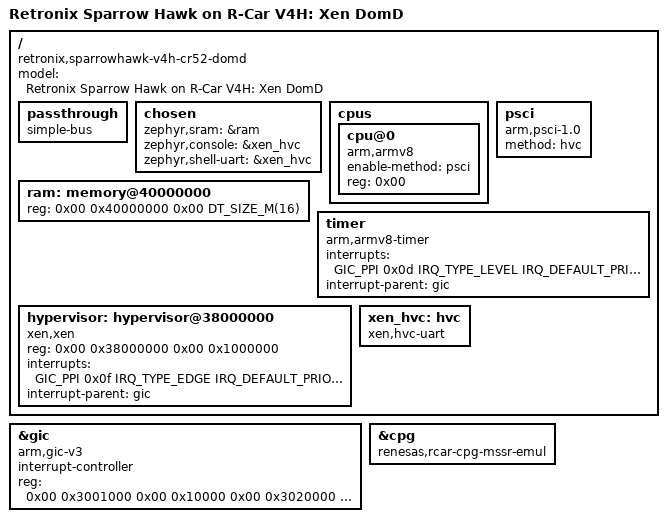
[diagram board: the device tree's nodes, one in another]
/*
 * Copyright (C) 2025 TOKITA Hiroshi
 *
 * SPDX-License-Identifier: Apache-2.0
 */

#include <mem.h>
#include <zephyr/dt-bindings/gpio/gpio.h>
#include <zephyr/dt-bindings/clock/r8a779g0_cpg_mssr.h>

/ {
	compatible = "retronix,sparrowhawk-v4h-cr52-domd";
	model = "Retronix Sparrow Hawk on R-Car V4H: Xen DomD";

	passthrough {
		compatible = "simple-bus";
		ranges;
		#address-cells = <2>;
		#size-cells = <2>;
	};

	chosen {
		zephyr,sram = &ram;
		zephyr,console = &xen_hvc;
		zephyr,shell-uart = &xen_hvc;
	};

	cpus {
		#address-cells = <0x01>;
		#size-cells = <0x00>;

		cpu@0 {
			device_type = "cpu";
			compatible = "arm,armv8";
			enable-method = "psci";
			reg = <0x00>;
		};
	};

	psci {
		compatible = "arm,psci-1.0", "arm,psci-0.2", "arm,psci";
		method = "hvc";
	};

	ram: memory@40000000 {
		device_type = "memory";
		reg = <0x00 0x40000000 0x00 DT_SIZE_M(16)>;
	};

	timer {
		compatible = "arm,armv8-timer";
		interrupts = <GIC_PPI 0x0d IRQ_TYPE_LEVEL IRQ_DEFAULT_PRIORITY
			      GIC_PPI 0x0e IRQ_TYPE_LEVEL IRQ_DEFAULT_PRIORITY
			      GIC_PPI 0x0b IRQ_TYPE_LEVEL IRQ_DEFAULT_PRIORITY>;
		interrupt-parent = <&gic>;
	};

	hypervisor: hypervisor@38000000 {
		compatible = "xen,xen";
		reg = <0x00 0x38000000 0x00 0x1000000>;
		interrupts = <GIC_PPI 0x0f IRQ_TYPE_EDGE IRQ_DEFAULT_PRIORITY>;
		interrupt-parent = <&gic>;
	};

	xen_hvc: hvc {
		compatible = "xen,hvc-uart";
		status = "okay";
	};
};

&gic {
	compatible = "arm,gic-v3", "arm,gic";
	#interrupt-cells = <0x04>;
	#address-cells = <0x00>;
	interrupt-controller;
	reg = <0x00 0x3001000 0x00 0x10000 0x00 0x3020000 0x00 0x1000000>;
};

// Disable Original Serial device
/delete-node/ &hscif0;
/delete-node/ &hscif1;

&cpg {
	compatible = "renesas,rcar-cpg-mssr-emul";
	#clock-cells = <2>;
};


